# CY8C5868AXI_LP032 register map
File version: 0.1
CY8C58LP
Registers are 8-bit, read-write, no defined reset value unless marked. A register's access mark holds for its fields unless they carry their own. Offsets are from the block's base; lines under a group give offsets from that group; [hi:lo] are bit positions; {n}, {i} and the like mark numbered series; 'fields as' and 'values as' point back to an identical list; <NAME> marks a mode.

## Memory map
0x400043A3 LMotorPwm size 0xB64
0x400043A3 RMotorPwm size 0xB70
0x40006408 PiComs size 0x161
0x40006579 MotorControlReg size 0x1

## LMotorPwm
Base 0x400043A3
0x00 LMotorPwm_GLOBAL_ENABLE — PM.ACT.CFG
  [3:0] en_timer — Enable timer/counters.
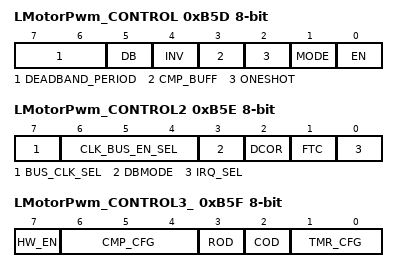
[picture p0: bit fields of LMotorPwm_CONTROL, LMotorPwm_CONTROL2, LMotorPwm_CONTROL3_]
0xB5D LMotorPwm_CONTROL — TMRx.CFG0
  [7:6] DEADBAND_PERIOD
  [5] DB — Deadband mode--Deadband phases phi1 and phi2 are outputted on CMP and TC output pins respectively.
    0=Timer (CMP and TC are output.); 1=Deadband (PHI1 (instead of CMP) and PHI2 (instead of TC) are output.)
  [4] INV — Invert sense of TIMEREN signal
  [3] CMP_BUFF — Buffer compare register. Compare register updates only on timer terminal count.
  [2] ONESHOT — Timer stops upon reaching stop condition defined by TMR_CFG bits. Can be restarted by asserting TIMER RESET or disabling and re-enabling block.
  [1] MODE ro — Mode. (0 = Timer; 1 = Comparator)
    0=Timer mode. CNT/CMP register holds timer count value.; 1=Comparator mode. CNT/CMP register holds comparator threshold value.
  [0] EN — Enables timer/comparator.
0xB5E LMotorPwm_CONTROL2 — TMRx.CFG1
  [7] BUS_CLK_SEL — Bus Clock selection.
  [6:4] CLK_BUS_EN_SEL — Digital Global Clock selection.
  [3] DBMODE — Deadband mode (asynchronous/synchronous). CMP output pin is also affected when not in deadband mode (CFG0.DEADBAND).
  [2] DCOR — Disable Clear on Read (DCOR) of Status Register SR0.
  [1] FTC — First Terminal Count (FTC). Setting this bit forces a single pulse on the TC pin when first enabled.
    0=Disable_FTC (Disable the single cycle pulse, which signifies the timer is starting.); 1=Enable_FTC (Enable the single cycle pulse, which signifies the timer is starting.)
  [0] IRQ_SEL — Irq selection. (0 = raw interrupts; 1 = status register interrupts)
0xB5F LMotorPwm_CONTROL3_ — TMRx.CFG2
  [7] HW_EN — When set Timer Enable controls counting.
  [6:4] CMP_CFG — Comparator configurations
    0=Equal (Compare Equal); 1=Less_than (Compare Less Than); 2=Less_than_or_equal (Compare Less Than or Equal .); 3=Greater (Compare Greater Than .); 4=Greater_than_or_equal (Compare Greater Than or Equal)
  [3] ROD — Reset On Disable (ROD). Resets internal state of output logic
  [2] COD — Clear On Disable (COD). Clears or gates outputs to zero.
  [1:0] TMR_CFG — Timer configuration (MODE = 0): 000 = Continuous; 001 = Pulsewidth; 010 = Period; 011 = Stop on IRQ
    0=Continuous (Timer runs while EN bit of CFG0 register is set to '1'.); 1=Pulsewidth (Timer runs from positive to negative edge of TIMEREN.); 2=Period (Timer runs from positive to positive edge of TIMEREN.); 3=Irq (Timer runs until IRQ.)
0xB61 LMotorPwm_PERIOD 16-bit — TMRx.PER0 - Assigned Period
0xB63 LMotorPwm_COMPARE 16-bit — TMRx.CNT_CMP0 - Assigned Compare Value

## RMotorPwm
Base 0x400043A3
0x00 RMotorPwm_GLOBAL_ENABLE — PM.ACT.CFG
  [3:0] en_timer — Enable timer/counters.
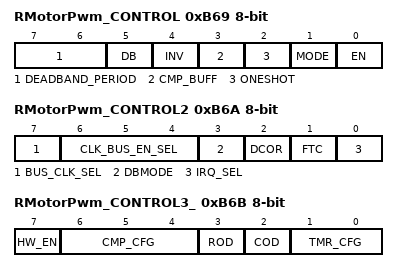
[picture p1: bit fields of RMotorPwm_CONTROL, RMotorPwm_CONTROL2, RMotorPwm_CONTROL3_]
0xB69 RMotorPwm_CONTROL — TMRx.CFG0
  fields as LMotorPwm.LMotorPwm_CONTROL
0xB6A RMotorPwm_CONTROL2 — TMRx.CFG1
  fields as LMotorPwm.LMotorPwm_CONTROL2
0xB6B RMotorPwm_CONTROL3_ — TMRx.CFG2
  fields as LMotorPwm.LMotorPwm_CONTROL3_
0xB6D RMotorPwm_PERIOD 16-bit — TMRx.PER0 - Assigned Period
0xB6F RMotorPwm_COMPARE 16-bit — TMRx.CNT_CMP0 - Assigned Compare Value

## MotorControlReg
Base 0x40006579
0x00 MotorControlReg_CONTROL_REG

## PiComs
Base 0x40006408
0x00 PiComs_TX_DATA — SPIS TX Data
0x00 PiComs_RX_DATA — SPIS RX Data
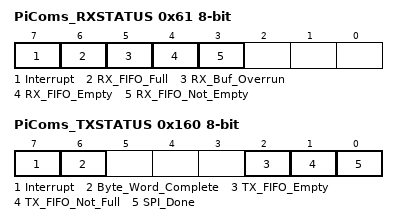
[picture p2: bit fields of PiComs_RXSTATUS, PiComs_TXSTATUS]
0x61 PiComs_RXSTATUS — SPIS RX Status Register
  [7] Interrupt ro — Set when interrupt occurs
  [6] RX_FIFO_Full ro — Set when the RX Data FIFO is full
  [5] RX_Buf_Overrun ro — Set when RX Data has overrun the 4 byte/word FIFO without being moved to the RX buffer cmemory array (if one exists)
  [4] RX_FIFO_Empty ro — Set when the RX Data FIFO is empty
  [3] RX_FIFO_Not_Empty ro — Set when the RX Data FIFO is not empty. That is, at least one byte/word is in the RX FIFO
0x160 PiComs_TXSTATUS — SPIS TX Status Register
  [7] Interrupt ro — Set when interrupt occurs
  [6] Byte_Word_Complete ro — Set when a byte/word transmit has completed
  [2] TX_FIFO_Empty ro — Set when the TX Data FIFO is empty
  [1] TX_FIFO_Not_Full ro — Set when the TX Data FIFO is not full
  [0] SPI_Done ro — Set when all of the data in the transmit FIFO has been sent. Set when Byte/Word Complete has been set and TX Data FIFO is empty
